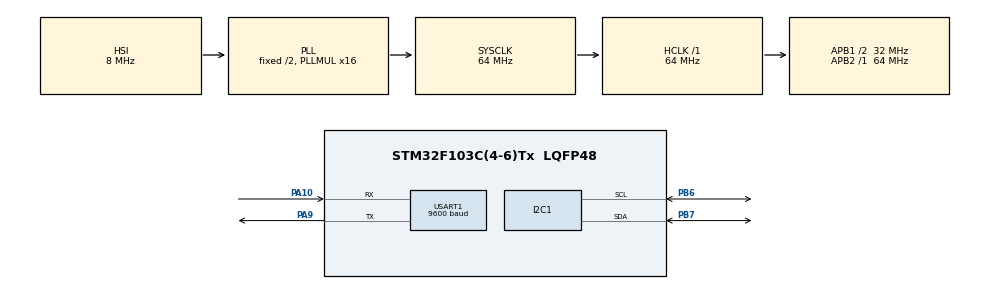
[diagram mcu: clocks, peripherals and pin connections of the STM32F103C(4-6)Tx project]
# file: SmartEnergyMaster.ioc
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I2C1.I2C_Mode=I2C_Fast
Mcu.Family=STM32F1
Mcu.Name=STM32F103C(4-6)Tx
Mcu.Package=LQFP48
NVIC.PriorityGroup=NVIC_PRIORITYGROUP_4
PA10.Mode=Asynchronous
PA10.Signal=USART1_RX
PA9.Mode=Asynchronous
PA9.Signal=USART1_TX
PB6.Mode=I2C
PB6.Signal=I2C1_SCL
PB7.Mode=I2C
PB7.Signal=I2C1_SDA
ProjectManager.HeapSize=0x200
ProjectManager.StackSize=0x400
ProjectManager.TargetToolchain=STM32CubeIDE
RCC.AHBFreq_Value=64000000
RCC.APB1CLKDivider=RCC_HCLK_DIV2
RCC.APB1Freq_Value=32000000
RCC.APB1TimFreq_Value=64000000
RCC.APB2Freq_Value=64000000
RCC.APB2TimFreq_Value=64000000
RCC.HCLKFreq_Value=64000000
RCC.PLLMUL=RCC_PLL_MUL16
RCC.SYSCLKFreq_VALUE=64000000
RCC.SYSCLKSource=RCC_SYSCLKSOURCE_PLLCLK
RCC.USBFreq_Value=64000000
USART1.BaudRate=9600
USART1.VirtualMode=VM_ASYNC
VP_SYS_VS_ND.Mode=No_Debug
board=custom

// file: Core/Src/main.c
/* USER CODE BEGIN Header */
/**
  ******************************************************************************
  * @file           : main.c
  * @brief          : Main program body
  ******************************************************************************
  * @attention
  *
  * Copyright (c) 2025 STMicroelectronics.
  * All rights reserved.
  *
  * This software is licensed under terms that can be found in the LICENSE file
  * in the root directory of this software component.
  * If no LICENSE file comes with this software, it is provided AS-IS.
  *
  ******************************************************************************
  */
/* USER CODE END Header */
#include "main.h"
#include "i2c.h"
#include "usart.h"
#include "gpio.h"
#include "ESP8226.h"
#include "ADE7953.h"
#include "SSD1306.h"

void SystemClock_Config(void);

int main(void)
{

  /* MCU Configuration--------------------------------------------------------*/

  /* Reset of all peripherals, Initializes the Flash interface and the Systick. */
  HAL_Init();

  /* Configure the system clock */
  SystemClock_Config();

  /* Initialize all configured peripherals */
  MX_GPIO_Init();
  MX_I2C1_Init();
  MX_USART1_UART_Init();
  /* USER CODE BEGIN 2 */
  ESP8266_Init(&huart1);
  ESP8266_ConnectWiFi();
  SSD1306_Init(&hi2c1);
  SSD1306_Clear();

  /* USER CODE END 2 */

  /* Infinite loop */
  while (1)
  {
	  uint32_t voltage = 0, current = 0, power = 0;
	  char buffer[100];

	  ADE7953_ReadRegister(&hi2c1, ADE7953_REG_VRMS, &voltage, 3);
	  ADE7953_ReadRegister(&hi2c1, ADE7953_REG_IRMSA, &current, 3);
	  ADE7953_ReadRegister(&hi2c1, ADE7953_REG_WATT, &power, 3);

	  sprintf(buffer, "GET /upload?V=%lu&C=%lu&P=%lu HTTP/1.1\r\nHost: %s\r\n\r\n",
			  voltage, current, power, SERVER_IP);

	  ESP8266_SendCommand("AT+CIPSTART=\"TCP\",\"your_server.com\",80\r\n", "OK", 2000);
	  ESP8266_SendData(buffer);
	  ESP8266_CloseConnection();

	  // Display on OLED
	  SSD1306_Clear();
	  SSD1306_SetCursor(0, 0);
	  SSD1306_Print("Voltage:");
	  SSD1306_SetCursor(0, 2);
	  sprintf(buffer, "%lu V", voltage);
	  SSD1306_Print(buffer);

	  HAL_Delay(5000);
  }
}

void SystemClock_Config(void)
{
  RCC_OscInitTypeDef RCC_OscInitStruct = {0};
  RCC_ClkInitTypeDef RCC_ClkInitStruct = {0};

  /** Initializes the RCC Oscillators according to the specified parameters
  * in the RCC_OscInitTypeDef structure.
  */
  RCC_OscInitStruct.OscillatorType = RCC_OSCILLATORTYPE_HSI;
  RCC_OscInitStruct.HSIState = RCC_HSI_ON;
  RCC_OscInitStruct.HSICalibrationValue = RCC_HSICALIBRATION_DEFAULT;
  RCC_OscInitStruct.PLL.PLLState = RCC_PLL_ON;
  RCC_OscInitStruct.PLL.PLLSource = RCC_PLLSOURCE_HSI_DIV2;
  RCC_OscInitStruct.PLL.PLLMUL = RCC_PLL_MUL16;
  if (HAL_RCC_OscConfig(&RCC_OscInitStruct) != HAL_OK)
  {
    Error_Handler();
  }

  /** Initializes the CPU, AHB and APB buses clocks
  */
  RCC_ClkInitStruct.ClockType = RCC_CLOCKTYPE_HCLK|RCC_CLOCKTYPE_SYSCLK
                              |RCC_CLOCKTYPE_PCLK1|RCC_CLOCKTYPE_PCLK2;
  RCC_ClkInitStruct.SYSCLKSource = RCC_SYSCLKSOURCE_PLLCLK;
  RCC_ClkInitStruct.AHBCLKDivider = RCC_SYSCLK_DIV1;
  RCC_ClkInitStruct.APB1CLKDivider = RCC_HCLK_DIV2;
  RCC_ClkInitStruct.APB2CLKDivider = RCC_HCLK_DIV1;

  if (HAL_RCC_ClockConfig(&RCC_ClkInitStruct, FLASH_LATENCY_2) != HAL_OK)
  {
    Error_Handler();
  }
}

void Error_Handler(void)
{
  __disable_irq();
  while (1)
  {
  }
}
